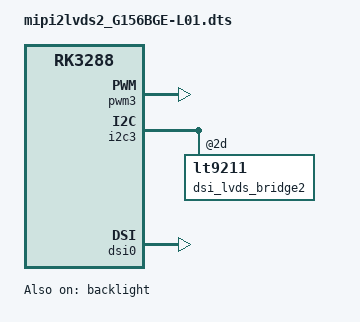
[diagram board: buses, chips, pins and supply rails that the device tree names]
/dts-v1/;
/plugin/;
/ {
	compatible = "rockchip,rk3288-evb-android-rk808-edp", "rockchip,rk3288";

	fragment@0 {
		target = <&pwm3>;
		__overlay__ {
			status = "okay";
		};
	};
	fragment@1 {
		target = <&backlight>;
		__overlay__ {
			status = "okay";
			pwms = <&pwm0 0 5000000 0>;
            power-sequence-reverse;
            enable_delay = <10>;
            disable_delay = <10>;
            minimal-brightness-level = <30>;
		};
	};
	fragment@2 {
		target = <&i2c3>;
		__overlay__ {
			status = "okay";
			dsi_lvds_bridge2: lt9211@2d {
				status = "okay";
				dsi-lanes = <2>;
				lvds-format = <2>;//VESA
				lvds-bpp = <24>;
                de-mode;
				//test-pattern;
			};
		};
	};
	fragment@3 {
		target = <&dsi0>;
		__overlay__ {
			status = "okay";
			panel@0 {
				backlight = <&backlight>;

				width-mm = <344>;
				height-mm = <193>;
				bpc=<8>;
				bus-format = <0x100a>;//<MEDIA_BUS_FMT_RGB888_1X24>;
				dsi,flags = <0x3>;
				dsi,format = <0>;
				dsi,lanes = <2>;

                t1=<1>;//VCC on to start lvds signal
				t2=<500>;//LVDS signal(start) to turn Backlihgt on
				t3=<200>;//Backlihgt(off) to stop lvds signal
				t4=<1>;//LVDS signal to turn VCC off
				t5=<1000>;//VCC off to turn VCC on

				display-timings {
					native-mode = <&timing84>;

					timing84: timing84  {
						clock-frequency = <76000000>;
						hactive = <1366>;
						vactive = <768>;
						hfront-porch = <80>;
						hback-porch = <80>;
						hsync-len = <34>;
						vfront-porch = <15>;
						vsync-len = <8>;
						vback-porch = <15>;
						hsync-active = <0>;
						vsync-active = <0>;
						de-active = <1>;
						pixelclk-active = <0>;
					};
				};
			};
		};
	};
};
